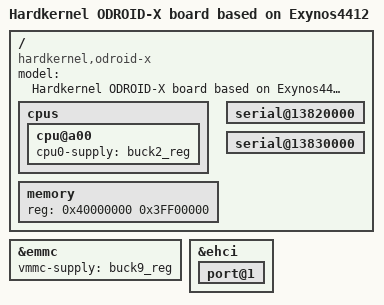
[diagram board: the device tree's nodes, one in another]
/*
 * Hardkernel's Exynos4412 based ODROID-X board device tree source
 *
 * Copyright (c) 2012 Dongjin Kim <tobetter@gmail.com>
 *
 * Device tree source file for Hardkernel's ODROID-X board which is based
 * on Samsung's Exynos4412 SoC.
 *
 * This program is free software; you can redistribute it and/or modify
 * it under the terms of the GNU General Public License version 2 as
 * published by the Free Software Foundation.
*/

/dts-v1/;
#include "exynos4412.dtsi"
#include "exynos4412-uav-common.dtsi"

/ {
	model = "Hardkernel ODROID-X board based on Exynos4412";
	compatible = "hardkernel,odroid-x", "samsung,exynos4412", "samsung,exynos4";

	cpus {
		cpu@a00 {
			cpu0-supply = <&buck2_reg>;
		};
	};

	memory {
		reg = <0x40000000 0x3FF00000>;
    };

	serial@13820000 {
		status = "okay";
	};

	serial@13830000 {
		status = "okay";
    };
};

&emmc {
    vmmc-supply = <&buck9_reg>;
};

&ehci {
	port@1 {
		status = "okay";
	};
};
